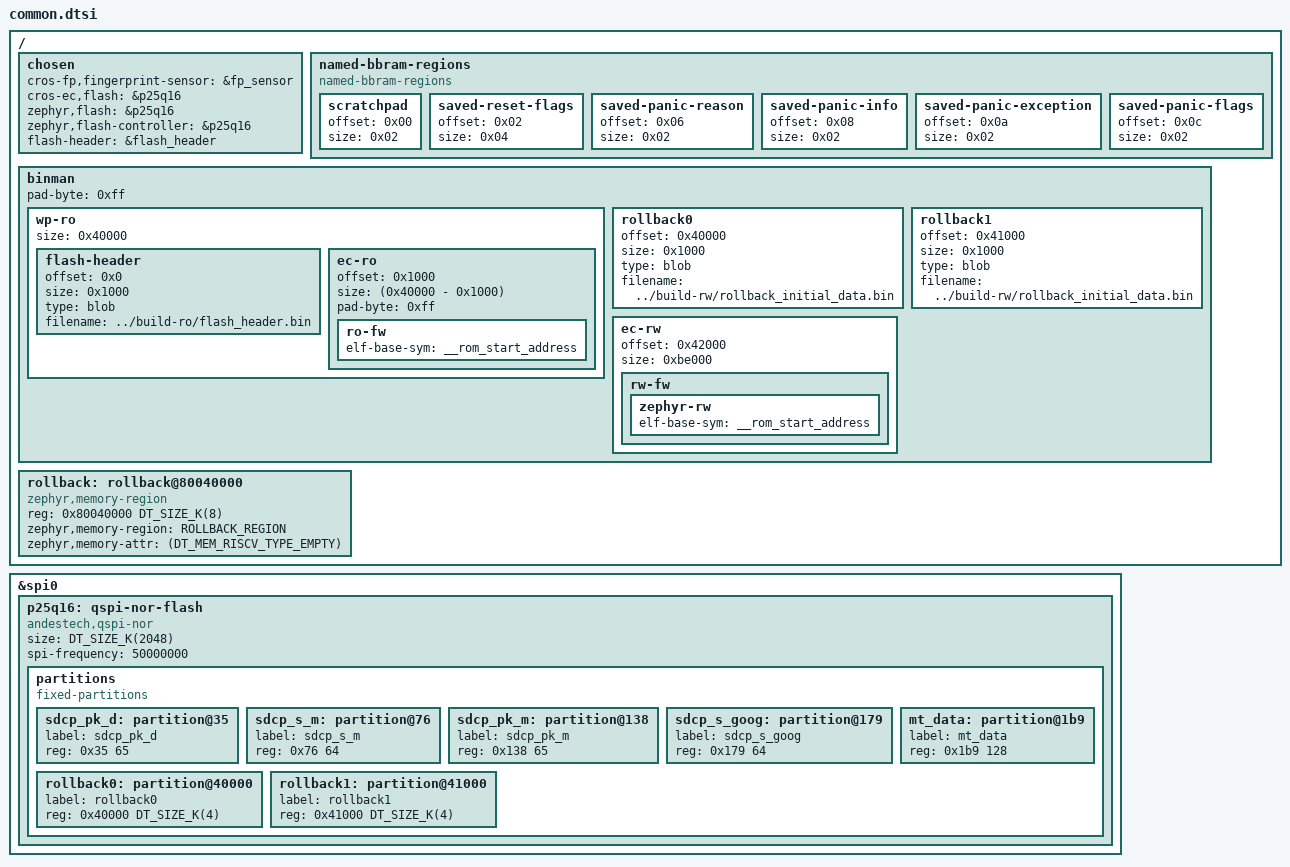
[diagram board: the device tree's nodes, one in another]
/* Copyright 2025 The ChromiumOS Authors.
 * Use of this source code is governed by a BSD-style license that can be
 * found in the LICENSE file.
 */

#include <egis/common_priv.dtsi>
#include <zephyr/dt-bindings/memory-attr/memory-attr-riscv.h>

#include "soc.dtsi"
#include "gpio.dtsi"
#include "rwsig.dtsi"
#include "ascp.dtsi"

#include <cros/integrated_fwid.dtsi>
#include <cros/integrated_ro_frid.dtsi>

/ {
	chosen {
		cros-fp,fingerprint-sensor = &fp_sensor;
		cros-ec,flash = &p25q16;
		zephyr,flash = &p25q16;
		zephyr,flash-controller = &p25q16;
		flash-header = &flash_header;
	};

	named-bbram-regions {
		compatible = "named-bbram-regions";

		scratchpad {
			offset = <0x00>;
			size = <0x02>;
		};
		saved-reset-flags {
			offset = <0x02>;
			size = <0x04>;
		};
		saved-panic-reason {
			offset = <0x06>;
			size = <0x02>;
		};
		saved-panic-info {
			offset = <0x08>;
			size = <0x02>;
		};
		saved-panic-exception {
			offset = <0x0a>;
			size = <0x02>;
		};
		saved-panic-flags {
			offset = <0x0c>;
			size = <0x02>;
		};
	};


	/* Map the sections to fit the flash chip protection table */
	binman {
		/* SDCP flash header 4kB */

		/* Fill 1/4 of 1MB */
		wp-ro {
			size = <0x40000>;
			flash-header {
				offset = <0x0>;
				size = <0x1000>;
				type = "blob";
				filename = "../build-ro/flash_header.bin";
			};
			ec-ro {
				offset = <0x1000>;
				size = <(0x40000 - 0x1000)>;
				pad-byte = <0xff>;
				ro-fw {
					/*
					 * Clang doesn't emit STT_SECTION symbols (also
					 * called 'section symbols'), so 'rom_start'
					 * symbol is not available. Fortunately, Zephyr
					 * linker scripts provide '__rom_start_address'
					 * symbol which points to the beginning of
					 * 'rom_start' section.
					 */
					elf-base-sym = "__rom_start_address";
				};
			};
		};

		/* Use the rest for RW + Rollbacks. Erase unit(4kB) per rollback */
		rollback0 {
			offset = <0x40000>;
			size = <0x1000>;
			type = "blob";
			filename = "../build-rw/rollback_initial_data.bin";
		};

		rollback1 {
			offset = <0x41000>;
			size = <0x1000>;
			type = "blob";
			filename = "../build-rw/rollback_initial_data.bin";
		};

		ec-rw {
			offset = <0x42000>;
			size = <0xbe000>;
			rw-fw {
				/*
				 * Clang doesn't emit STT_SECTION symbols (also
				 * called 'section symbols'), so 'rom_start'
				 * symbol is not available. Fortunately, Zephyr
				 * linker scripts provide '__rom_start_address'
				 * symbol which points to the beginning of
				 * 'rom_start' section.
				 */
				zephyr-rw {
					elf-base-sym = "__rom_start_address";
				};
			};
		};
		pad-byte = <0xff>;
	};
};

&spi0 {
	p25q16: qspi-nor-flash {
		compatible = "andestech,qspi-nor", "jedec,spi-nor";
		size = <DT_SIZE_K(2048)>;
		spi-frequency = <50000000>;
		status = "okay";
	};
};

&p25q16 {
	partitions {
		compatible = "fixed-partitions";
		#address-cells = <1>;
		#size-cells = <1>;

		sdcp_pk_d: partition@35 {
			label = "sdcp_pk_d";
			reg = <0x35 65>;
		};

		sdcp_s_m: partition@76 {
			label = "sdcp_s_m";
			reg = <0x76 64>;
		};

		sdcp_pk_m: partition@138 {
			label = "sdcp_pk_m";
			reg = <0x138 65>;
		};

		sdcp_s_goog: partition@179 {
			label = "sdcp_s_goog";
			reg = <0x179 64>;
		};

		mt_data: partition@1b9 {
			label = "mt_data";
			reg = <0x1b9 128>;
		};

		rollback0: partition@40000 {
			label = "rollback0";
			reg = <0x40000 DT_SIZE_K(4)>;
		};

		rollback1: partition@41000 {
			label = "rollback1";
			reg = <0x41000 DT_SIZE_K(4)>;
		};
	};
};

/ {
	rollback: rollback@80040000 {
		compatible = "zephyr,memory-region";
		reg = <0x80040000 DT_SIZE_K(8)>;
		zephyr,memory-region = "ROLLBACK_REGION";
		/*
		 * This region is only used in M-mode, not U-mode. It has no
		 * access permissions (no read, no write, and no execute) unless
		 * unlocked, at which point read and write access are enabled.
		 */
		zephyr,memory-attr = <(DT_MEM_RISCV_TYPE_EMPTY)>;
	};
};
